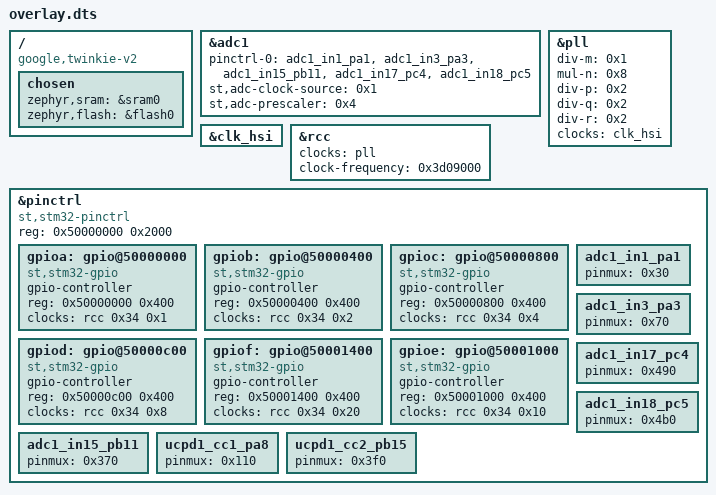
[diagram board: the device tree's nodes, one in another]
/ {
	compatible = "google,twinkie-v2";
	chosen {
		zephyr,sram = &sram0;
		zephyr,flash = &flash0;
	};
};
&adc1{
	status = "okay";
	#address-cells = < 0x1 >;
	#size-cells = < 0x0 >;
	pinctrl-0 = < &adc1_in1_pa1 &adc1_in3_pa3 &adc1_in15_pb11 &adc1_in17_pc4 &adc1_in18_pc5 >;
	pinctrl-names = "default";
	st,adc-clock-source = < 0x1 >;
	st,adc-prescaler = < 0x4 >;
};
&pll{
	status = "okay";
	div-m = < 0x1 >;
	mul-n = < 0x8 >;
	div-p = < 0x2 >;
	div-q = < 0x2 >;
	div-r = < 0x2 >;
	clocks = < &clk_hsi >;
};
&clk_hsi{
	status = "okay";
};
&rcc{
	clocks = < &pll >;
	clock-frequency = < 0x3d09000 >;
};
&pinctrl{
	compatible = "st,stm32-pinctrl";
	#address-cells = < 0x1 >;
	#size-cells = < 0x1 >;
	reg = < 0x50000000 0x2000 >;
	gpioa: gpio@50000000 {
		compatible = "st,stm32-gpio";
		gpio-controller;
		#gpio-cells = < 0x2 >;
		reg = < 0x50000000 0x400 >;
		clocks = < &rcc 0x34 0x1 >;
	};
	gpiob: gpio@50000400 {
		compatible = "st,stm32-gpio";
		gpio-controller;
		#gpio-cells = < 0x2 >;
		reg = < 0x50000400 0x400 >;
		clocks = < &rcc 0x34 0x2 >;
	};
	gpioc: gpio@50000800 {
		compatible = "st,stm32-gpio";
		gpio-controller;
		#gpio-cells = < 0x2 >;
		reg = < 0x50000800 0x400 >;
		clocks = < &rcc 0x34 0x4 >;
	};
	gpiod: gpio@50000c00 {
		compatible = "st,stm32-gpio";
		gpio-controller;
		#gpio-cells = < 0x2 >;
		reg = < 0x50000c00 0x400 >;
		clocks = < &rcc 0x34 0x8 >;
	};
	gpiof: gpio@50001400 {
		compatible = "st,stm32-gpio";
		gpio-controller;
		#gpio-cells = < 0x2 >;
		reg = < 0x50001400 0x400 >;
		clocks = < &rcc 0x34 0x20 >;
	};
	gpioe: gpio@50001000 {
		compatible = "st,stm32-gpio";
		gpio-controller;
		#gpio-cells = < 0x2 >;
		reg = < 0x50001000 0x400 >;
		clocks = < &rcc 0x34 0x10 >;
	};
	adc1_in1_pa1: adc1_in1_pa1 {
		pinmux = < 0x30 >;
	};
	adc1_in3_pa3: adc1_in3_pa3 {
		pinmux = < 0x70 >;
	};
	adc1_in15_pb11: adc1_in15_pb11 {
		pinmux = < 0x370 >;
	};
	adc1_in17_pc4: adc1_in17_pc4 {
		pinmux = < 0x490 >;
	};
	adc1_in18_pc5: adc1_in18_pc5 {
		pinmux = < 0x4b0 >;
	};
	ucpd1_cc1_pa8: ucpd1_cc1_pa8 {
		pinmux = < 0x110 >;
	};
	ucpd1_cc2_pb15: ucpd1_cc2_pb15 {
		pinmux = < 0x3f0 >;
	};
};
